# ESW3120 register map
Vendor: Shanghai Eastsoft Microelectronics Co.,Ltd.; Series: ARMCM3; File version: 1.2
CPU: CM3 r2p1, little endian, MPU, no FPU, 4 interrupt priority bits
Registers are 32-bit, read-write, reset 0x0 unless marked. A register's access mark holds for its fields unless they carry their own. Offsets are from the block's base; [hi:lo] are bit positions; {n}, {i} and the like mark numbered series.

## QSPI
Base 0x4000E000
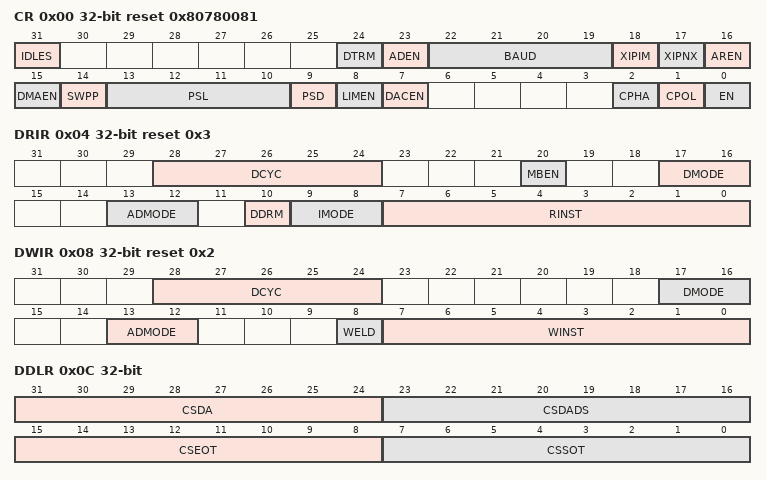
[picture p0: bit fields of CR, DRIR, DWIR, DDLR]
0x00 CR reset 0x80780081
  [31] IDLES read, [24] DTRM, [23] ADEN, [22:19] BAUD, [18] XIPIM, [17] XIPNX, [16] AREN, [15] DMAEN, [14] SWPP, [13:10] PSL, [9] PSD, [8] LIMEN, [7] DACEN, [2] CPHA, [1] CPOL, [0] EN
0x04 DRIR reset 0x3
  [28:24] DCYC, [20] MBEN, [17:16] DMODE, [13:12] ADMODE, [10] DDRM, [9:8] IMODE, [7:0] RINST
0x08 DWIR reset 0x2
  [28:24] DCYC, [17:16] DMODE, [13:12] ADMODE, [8] WELD, [7:0] WINST
0x0C DDLR
  [31:24] CSDA, [23:16] CSDADS, [15:8] CSEOT, [7:0] CSSOT
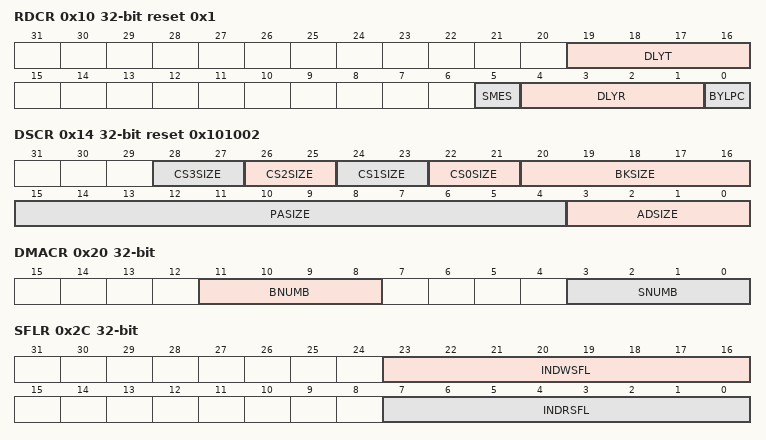
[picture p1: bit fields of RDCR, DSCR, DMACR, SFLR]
0x10 RDCR reset 0x1
  [19:16] DLYT, [5] SMES, [4:1] DLYR, [0] BYLPC
0x14 DSCR reset 0x101002
  [2n+22:2n+21] CS{n}SIZE (n=0..3), [20:16] BKSIZE, [15:4] PASIZE, [3:0] ADSIZE
0x18 SPR reset 0x20
  [5:0] SRAMPS
0x1C IATR
  [31:0] INDTAD
0x20 DMACR
  [11:8] BNUMB, [3:0] SNUMB
0x24 RAR
  [31:0] READDR
0x28 MBR
  [7:0] MODEB
0x2C SFLR read
  [23:16] INDWSFL, [7:0] INDRSFL
0x30 TXHR reset 0x1
  [4:0] TXTH
0x34 RXHR reset 0x1
  [4:0] RXTH
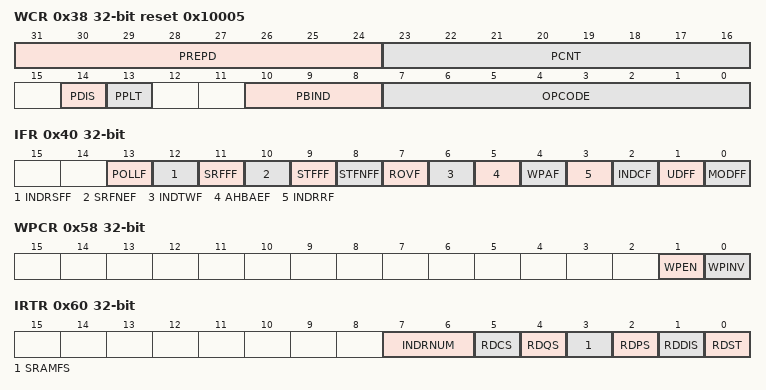
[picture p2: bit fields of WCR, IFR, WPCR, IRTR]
0x38 WCR reset 0x10005
  [31:24] PREPD, [23:16] PCNT, [14] PDIS, [13] PPLT, [10:8] PBIND, [7:0] OPCODE
0x3C PER reset 0xFFFFFFFF
  [31:0] PCYCN
0x40 IFR
  [13] POLLF, [12] INDRSFF, [11] SRFFF, [10] SRFNEF, [9] STFFF, [8] STFNFF, [7] ROVF, [6] INDTWF, [5] AHBAEF, [4] WPAF, [3] INDRRF, [2] INDCF, [1] UDFF, [0] MODFF
0x44 IMR
  [13:0] INTEN
0x50 WPLR
  [31:0] LBLKNUM
0x54 WPHR
  [31:0] HBLKNUM
0x58 WPCR
  [1] WPEN, [0] WPINV
0x60 IRTR write1
  [7:6] INDRNUM read, [5] RDCS rw, [4] RDQS read, [3] SRAMFS rw, [2] RDPS read, [1] RDDIS, [0] RDST
0x64 IRTWR
  [31:0] VAULE
0x68 IRTSAR
  [31:0] ADDR
0x6C IRTNR
  [31:0] NUM
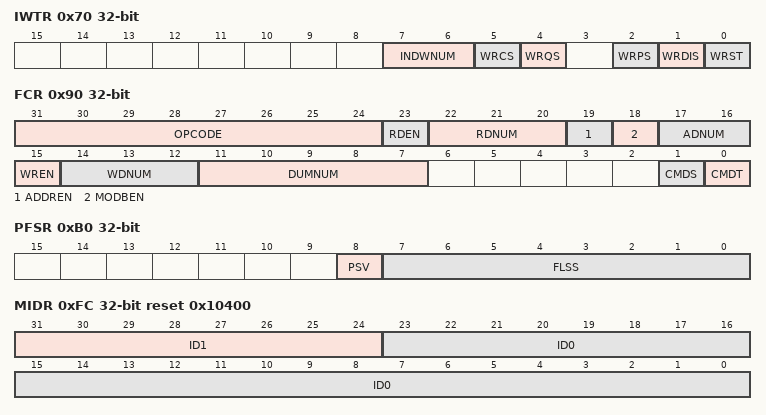
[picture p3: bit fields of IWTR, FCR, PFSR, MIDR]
0x70 IWTR write1
  [7:6] INDWNUM read, [5] WRCS rw, [4] WRQS read, [2] WRPS read, [1] WRDIS, [0] WRST
0x74 IWTWR reset 0xFFFFFFFF
  [31:0] VAULE
0x78 IWTSAR
  [31:0] ADDR
0x7C IWTNR
  [31:0] NUM
0x80 ITARR reset 0x4
  [3:0] RNGW
0x90 FCR write1
  [31:24] OPCODE rw, [23] RDEN rw, [22:20] RDNUM rw, [19] ADDREN rw, [18] MODBEN rw, [17:16] ADNUM rw, [15] WREN rw, [14:12] WDNUM rw, [11:7] DUMNUM rw, [1] CMDS read, [0] CMDT
0x94 FCAR
  [31:0] CMDADR
0xA0 FCRLR read
  [31:0] CMDDL
0xA4 FCRHR read
  [31:0] CMDDH
0xA8 FCWLR read
  [31:0] CMDDL
0xAC FCWHR read
  [31:0] CMDDH
0xB0 PFSR read
  [8] PSV, [7:0] FLSS
0xFC MIDR read reset 0x10400
  [31:24] ID1, [23:0] ID0

## TK
Base 0x40008C00
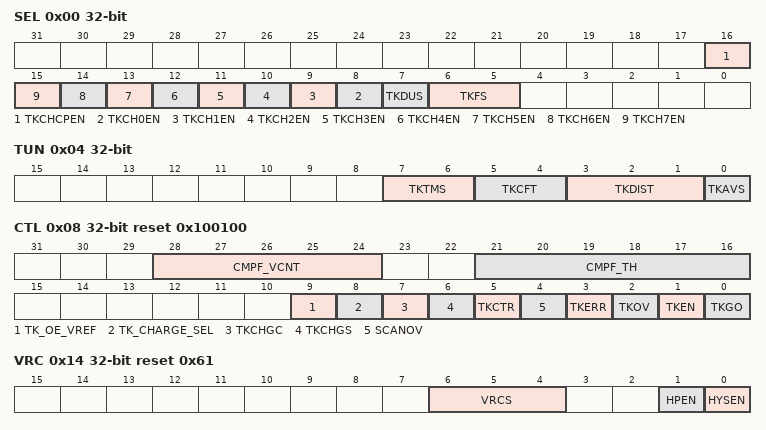
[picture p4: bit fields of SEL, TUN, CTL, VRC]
0x00 SEL
  [16] TKCHCPEN, [n+8] TKCH{n}EN (n=0..7), [7] TKDUS, [6:5] TKFS
0x04 TUN
  [7:6] TKTMS, [5:4] TKCFT, [3:1] TKDIST, [0] TKAVS
0x08 CTL reset 0x100100
  [28:24] CMPF_VCNT read, [21:16] CMPF_TH, [9] TK_OE_VREF, [8] TK_CHARGE_SEL, [7] TKCHGC, [6] TKCHGS, [5] TKCTR, [4] SCANOV read, [3] TKERR read, [2] TKOV read, [1] TKEN, [0] TKGO
0x0C DA read
  [23:0] TKDA
0x10 MOD reset 0xFFFFFFF
  [27:0] TKMOD
0x14 VRC reset 0x61
  [6:4] VRCS, [1] HPEN, [0] HYSEN
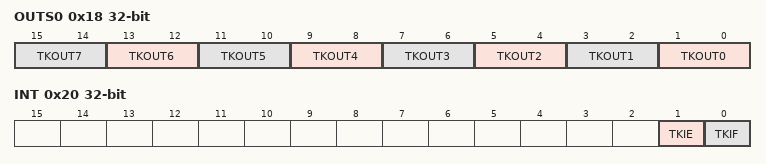
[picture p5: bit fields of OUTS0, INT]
0x18 OUTS0
  [2n+1:2n] TKOUT{n} (n=0..7)
0x20 INT write1
  [1] TKIE rw, [0] TKIF read-clear-write1
0x24 SCT read
  [19:0] SCCNT

## PMU
Base 0x40080C00
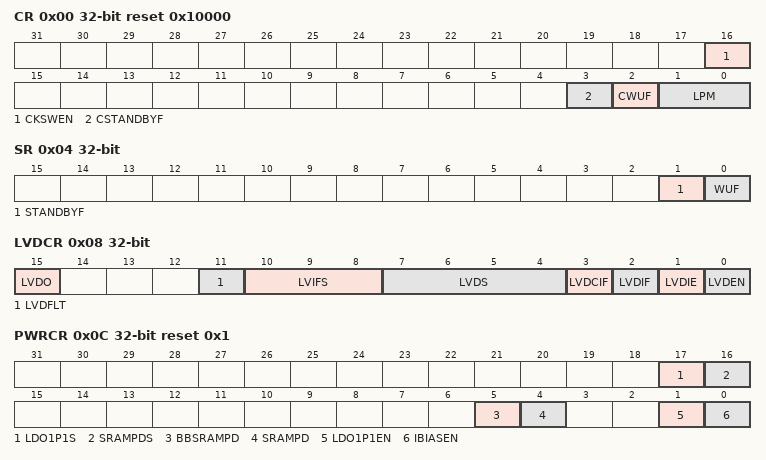
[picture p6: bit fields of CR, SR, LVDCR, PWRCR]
0x00 CR reset 0x10000
  [16] CKSWEN, [3] CSTANDBYF trigger-write1, [2] CWUF trigger-write1, [1:0] LPM
0x04 SR read
  [1] STANDBYF, [0] WUF
0x08 LVDCR
  [15] LVDO read, [11] LVDFLT, [10:8] LVIFS, [7:4] LVDS, [3] LVDCIF trigger-write1, [2] LVDIF read, [1] LVDIE, [0] LVDEN
0x0C PWRCR reset 0x1
  [17] LDO1P1S read, [16] SRAMPDS read, [5] BBSRAMPD, [4] SRAMPD, [1] LDO1P1EN, [0] IBIASEN
0x10 TWUR reset 0x2
  [11:0] WKT
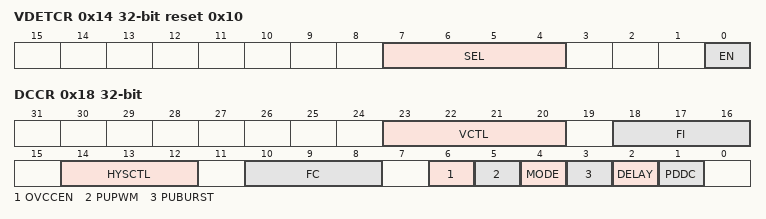
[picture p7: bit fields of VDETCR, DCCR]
0x14 VDETCR reset 0x10
  [7:4] SEL, [0] EN
0x18 DCCR
  [23:20] VCTL, [18:16] FI, [14:12] HYSCTL, [10:8] FC, [6] OVCCEN, [5] PUPWM, [4] MODE, [3] PUBURST, [2] DELAY, [1] PDDC

## PDM2PCM
Base 0x40009000
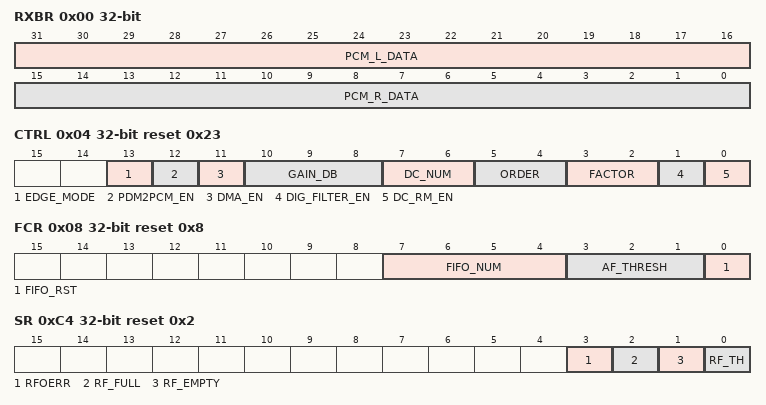
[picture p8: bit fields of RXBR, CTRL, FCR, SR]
0x00 RXBR read
  [31:16] PCM_L_DATA, [15:0] PCM_R_DATA
0x04 CTRL reset 0x23
  [13] EDGE_MODE, [12] PDM2PCM_EN, [11] DMA_EN, [10:8] GAIN_DB, [7:6] DC_NUM, [5:4] ORDER, [3:2] FACTOR, [1] DIG_FILTER_EN, [0] DC_RM_EN
0x08 FCR write reset 0x8
  [7:4] FIFO_NUM read, [3:1] AF_THRESH rw, [0] FIFO_RST
0x0C 0FILT reset 0x3FFB4
  [17:0] PDM2PCM_0FILT
0x10 1FILT reset 0x3FFD7
  [17:0] PDM2PCM_1FILT
0x14 2FILT reset 0xE
  [17:0] PDM2PCM_2FILT
0x18 3FILT reset 0x48
  [17:0] PDM2PCM_3FILT
0x1C 4FILT reset 0x6E
  [17:0] PDM2PCM_4FILT
0x20 5FILT reset 0x69
  [17:0] PDM2PCM_5FILT
0x24 6FILT reset 0x32
  [17:0] PDM2PCM_6FILT
0x28 7FILT reset 0x3FFD0
  [17:0] PDM2PCM_7FILT
0x2C 8FILT reset 0x3FF66
  [17:0] PDM2PCM_8FILT
0x30 9FILT reset 0x3FF26
  [17:0] PDM2PCM_9FILT
0x34 10FILT reset 0x3FF3D
  [17:0] PDM2PCM_10FILT
0x38 11FILT reset 0x3FFBC
  [17:0] PDM2PCM_11FILT
0x3C 12FILT reset 0x83
  [17:0] PDM2PCM_12FILT
0x40 13FILT reset 0x146
  [17:0] PDM2PCM_13FILT
0x44 14FILT reset 0x1A2
  [17:0] PDM2PCM_14FILT
0x48 15FILT reset 0x14C
  [17:0] PDM2PCM_15FILT
0x4C 16FILT reset 0x3C
  [17:0] PDM2PCM_16FILT
0x50 17FILT reset 0x3FEC5
  [17:0] PDM2PCM_17FILT
0x54 18FILT reset 0x3FD82
  [17:0] PDM2PCM_18FILT
0x58 19FILT reset 0x3FD1E
  [17:0] PDM2PCM_19FILT
0x5C 20FILT reset 0x3FDFF
  [17:0] PDM2PCM_20FILT
0x60 21FILT reset 0x9
  [17:0] PDM2PCM_21FILT
0x64 22FILT reset 0x28B
  [17:0] PDM2PCM_22FILT
0x68 23FILT reset 0x46F
  [17:0] PDM2PCM_23FILT
0x6C 24FILT reset 0x4AD
  [17:0] PDM2PCM_24FILT
0x70 25FILT reset 0x2C9
  [17:0] PDM2PCM_25FILT
0x74 26FILT reset 0x3FF2C
  [17:0] PDM2PCM_26FILT
0x78 27FILT reset 0x3FB23
  [17:0] PDM2PCM_27FILT
0x7C 28FILT reset 0x3F878
  [17:0] PDM2PCM_28FILT
0x80 29FILT reset 0x3F8B4
  [17:0] PDM2PCM_29FILT
0x84 30FILT reset 0x3FC61
  [17:0] PDM2PCM_30FILT
0x88 31FILT reset 0x292
  [17:0] PDM2PCM_31FILT
0x8C 32FILT reset 0x900
  [17:0] PDM2PCM_32FILT
0x90 33FILT reset 0xCC4
  [17:0] PDM2PCM_33FILT
0x94 34FILT reset 0xB80
  [17:0] PDM2PCM_34FILT
0x98 35FILT reset 0x482
  [17:0] PDM2PCM_35FILT
0x9C 36FILT reset 0x3F975
  [17:0] PDM2PCM_36FILT
0xA0 37FILT reset 0x3EE38
  [17:0] PDM2PCM_37FILT
0xA4 38FILT reset 0x3E7D4
  [17:0] PDM2PCM_38FILT
0xA8 39FILT reset 0x3EAD1
  [17:0] PDM2PCM_39FILT
0xAC 40FILT reset 0x3F97C
  [17:0] PDM2PCM_40FILT
0xB0 41FILT reset 0x12BF
  [17:0] PDM2PCM_41FILT
0xB4 42FILT reset 0x3209
  [17:0] PDM2PCM_42FILT
0xB8 43FILT reset 0x5062
  [17:0] PDM2PCM_43FILT
0xBC 44FILT reset 0x6661
  [17:0] PDM2PCM_44FILT
0xC0 45FILT reset 0x6E69
  [17:0] PDM2PCM_45FILT
0xC4 SR read reset 0x2
  [3] RFOERR, [2] RF_FULL, [1] RF_EMPTY, [0] RF_TH
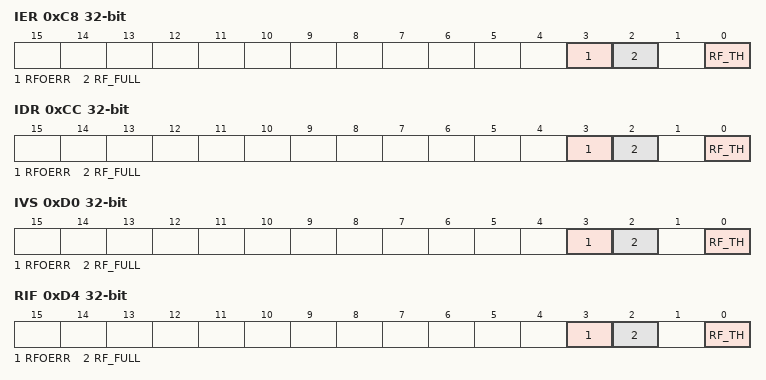
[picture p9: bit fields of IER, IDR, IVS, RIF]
0xC8 IER write1
  [3] RFOERR, [2] RF_FULL, [0] RF_TH
0xCC IDR write1
  [3] RFOERR, [2] RF_FULL, [0] RF_TH
0xD0 IVS read
  [3] RFOERR, [2] RF_FULL, [0] RF_TH
0xD4 RIF read
  [3] RFOERR, [2] RF_FULL, [0] RF_TH
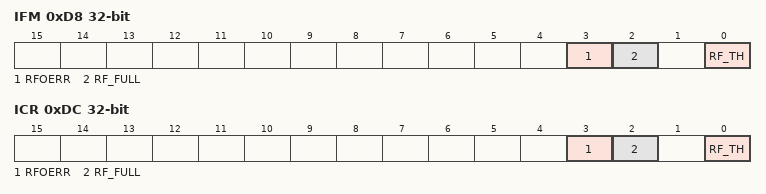
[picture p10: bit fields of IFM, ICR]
0xD8 IFM read
  [3] RFOERR, [2] RF_FULL, [0] RF_TH
0xDC ICR write1
  [3] RFOERR, [2] RF_FULL, [0] RF_TH
